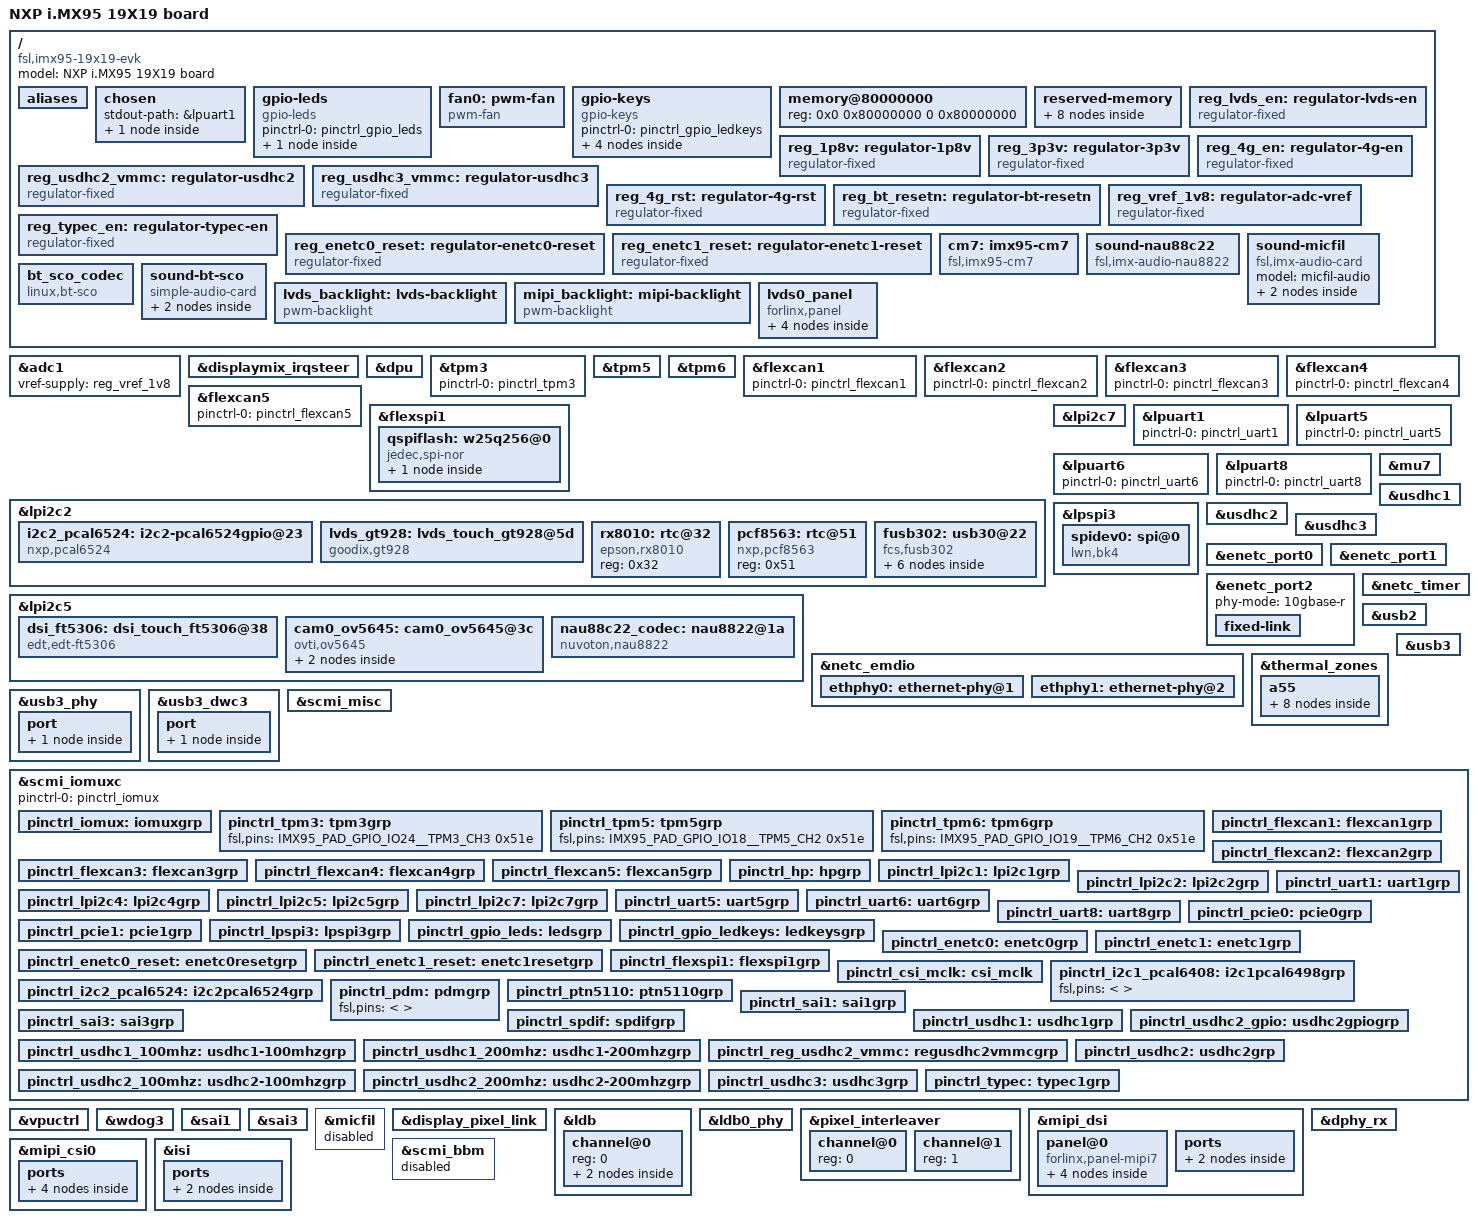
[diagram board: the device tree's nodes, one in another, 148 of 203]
// SPDX-License-Identifier: (GPL-2.0+ OR MIT)
/*
 * Copyright 2023 NXP
 */

/dts-v1/;

#include <dt-bindings/phy/phy-imx8-pcie.h>
#include <dt-bindings/pwm/pwm.h>
#include <dt-bindings/usb/pd.h>
#include "imx95.dtsi"

#define FALLING_EDGE		BIT(0)
#define RISING_EDGE		BIT(1)

#define BRD_SM_CTRL_SD3_WAKE		6	/*!< PCAL6408A-0 */
#define BRD_SM_CTRL_PCIE1_WAKE		7	/*!< PCAL6408A-4 */
#define BRD_SM_CTRL_BT_WAKE		8	/*!< PCAL6408A-5 */
#define BRD_SM_CTRL_PCIE2_WAKE		9	/*!< PCAL6408A-6 */
#define BRD_SM_CTRL_BUTTON		10	/*!< PCAL6408A-7 */

/ {
	model = "NXP i.MX95 19X19 board";
	compatible = "fsl,imx95-19x19-evk", "fsl,imx95";

	aliases {
		ethernet0 = &enetc_port0;
		ethernet1 = &enetc_port1;
		ethernet2 = &enetc_port2;
	};

	chosen {
		stdout-path = &lpuart1;
		#address-cells = <2>;
		#size-cells = <2>;
		/* will be updated by U-boot when booting Xen */
		module@0 {
			bootargs = "earlycon=xen console=hvc0 loglevel=8 root=/dev/mmcblk1p2 rw rootwait";
			compatible = "xen,linux-zimage", "xen,multiboot-module";
			reg = <0x00000000 0x9e000000 0x00000000 0x2000000>;
		};
	};

	gpio-leds {
		compatible = "gpio-leds";
		pinctrl-names = "default";
		pinctrl-0 = <&pinctrl_gpio_leds>;

		heartbeat {
			linux,default-trigger = "heartbeat";
			gpios = <&gpio3 27 GPIO_ACTIVE_HIGH>;
			default-state = "off";
		};
	};

	fan0: pwm-fan {
		compatible = "pwm-fan";
		cooling-min-state = <0>;
		cooling-max-state = <3>;
		#cooling-cells = <2>;
		pwms = <&tpm5 2 4000000 0>;
		cooling-levels = <0 80 160 255>;
	};

	gpio-keys {
		compatible = "gpio-keys";
		pinctrl-0 = <&pinctrl_gpio_ledkeys>;
		pinctrl-names = "default";

		button-a {
			gpios = <&gpio5 4 GPIO_ACTIVE_LOW>;
			label = "gpiokey-a";
			linux,code = <KEY_A>;
		};

		button-b {
			gpios = <&gpio5 5 GPIO_ACTIVE_LOW>;
			label = "gpiokey-b";
			linux,code = <KEY_B>;
		};

		button-c {
			gpios = <&gpio5 6 GPIO_ACTIVE_LOW>;
			label = "gpiokey-c";
			linux,code = <KEY_C>;
		};

		button-d {
			gpios = <&gpio5 7 GPIO_ACTIVE_LOW>;
			label = "gpiokey-d";
			linux,code = <KEY_D>;
		};
	};

	memory@80000000 {
		device_type = "memory";
		reg = <0x0 0x80000000 0 0x80000000>;
	};

	reserved-memory {
		#address-cells = <2>;
		#size-cells = <2>;
		ranges;

		linux_cma: linux,cma {
			compatible = "shared-dma-pool";
			reusable;
			size = <0 0x50000000>;
			alloc-ranges = <0 0x80000000 0 0x7F000000>;
			linux,cma-default;
		};

		vpu_boot: vpu_boot@a0000000 {
			reg = <0 0xa0000000 0 0x100000>;
			no-map;
		};

		vdev0vring0: vdev0vring0@88000000 {
			reg = <0 0x88000000 0 0x8000>;
			no-map;
		};

		vdev0vring1: vdev0vring1@88008000 {
			reg = <0 0x88008000 0 0x8000>;
			no-map;
		};

		vdev1vring0: vdev1vring0@88010000 {
			reg = <0 0x88010000 0 0x8000>;
			no-map;
		};

		vdev1vring1: vdev1vring1@88018000 {
			reg = <0 0x88018000 0 0x8000>;
			no-map;
		};

		rsc_table: rsc-table@88220000 {
			reg = <0 0x88220000 0 0x1000>;
			no-map;
		};

		vdevbuffer: vdevbuffer@88020000 {
			compatible = "shared-dma-pool";
			reg = <0 0x88020000 0 0x100000>;
			no-map;
		};
	};
/*
	reg_mipi_en: regulator-mipi-en {
		compatible = "regulator-fixed";
		regulator-name = "mipi-en";
		regulator-min-microvolt = <3300000>;
		regulator-max-microvolt = <3300000>;
		gpio = <&i2c2_pcal6524 17 GPIO_ACTIVE_HIGH>;
		enable-active-high;
		regulator-always-on;
	};
*/
	reg_lvds_en: regulator-lvds-en {
		compatible = "regulator-fixed";
		regulator-name = "lvds-en";
		regulator-min-microvolt = <3300000>;
		regulator-max-microvolt = <3300000>;
		gpio = <&i2c2_pcal6524 13 GPIO_ACTIVE_HIGH>;
		enable-active-high;
		regulator-always-on;
	};

	reg_1p8v: regulator-1p8v {
		compatible = "regulator-fixed";
		regulator-max-microvolt = <1800000>;
		regulator-min-microvolt = <1800000>;
		regulator-name = "+V1.8_SW";
	};

	reg_3p3v: regulator-3p3v {
		compatible = "regulator-fixed";
		regulator-max-microvolt = <3300000>;
		regulator-min-microvolt = <3300000>;
		regulator-name = "+V3.3_SW";
	};

        reg_usdhc2_vmmc: regulator-usdhc2 {
		compatible = "regulator-fixed";
		pinctrl-names = "default";
		pinctrl-0 = <&pinctrl_reg_usdhc2_vmmc>;
		regulator-name = "VDD_SD2_3V3";
		regulator-min-microvolt = <3300000>;
		regulator-max-microvolt = <3300000>;
		gpio = <&gpio3 7 GPIO_ACTIVE_HIGH>;
		off-on-delay-us = <12000>;
		enable-active-high;
	};

	reg_usdhc3_vmmc: regulator-usdhc3 {
		compatible = "regulator-fixed";
		regulator-name = "VDD_SD3_3V3";
		regulator-min-microvolt = <3300000>;
		regulator-max-microvolt = <3300000>;
		gpio = <&i2c2_pcal6524 4 GPIO_ACTIVE_HIGH>;
		enable-active-high;
	};

	reg_4g_en: regulator-4g-en {
		compatible = "regulator-fixed";
		regulator-name = "4g-en";
		regulator-min-microvolt = <3300000>;
		regulator-max-microvolt = <3300000>;
		gpio = <&i2c2_pcal6524 9 GPIO_ACTIVE_HIGH>;
		enable-active-high;
		regulator-always-on;
	};

	reg_4g_rst: regulator-4g-rst {
		compatible = "regulator-fixed";
		regulator-name = "4g-rst-3v3";
		regulator-min-microvolt = <3300000>;
		regulator-max-microvolt = <3300000>;
		gpio = <&i2c2_pcal6524 10 GPIO_ACTIVE_LOW>;
		enable-active-low;
		regulator-always-on;
	};

	reg_bt_resetn: regulator-bt-resetn {
		compatible = "regulator-fixed";
		regulator-name = "bt-resetn";
		regulator-min-microvolt = <3300000>;
		regulator-max-microvolt = <3300000>;
		gpio = <&i2c2_pcal6524 1 GPIO_ACTIVE_HIGH>;
		enable-active-high;
		regulator-always-on;
	};

/*
	reg_pcie0: regulator-pcie {
		compatible = "regulator-fixed";
		regulator-name = "PCIE_WLAN_EN";
		regulator-min-microvolt = <3300000>;
		regulator-max-microvolt = <3300000>;
		gpio = <&i2c7_pcal6524 6 GPIO_ACTIVE_HIGH>;
		enable-active-high;
		regulator-always-on;
	};
*/
	reg_vref_1v8: regulator-adc-vref {
		compatible = "regulator-fixed";
		regulator-name = "vref_1v8";
		regulator-min-microvolt = <1800000>;
		regulator-max-microvolt = <1800000>;
	};

	reg_typec_en: regulator-typec-en {
		compatible = "regulator-fixed";
		regulator-name = "typec-en";
		regulator-min-microvolt = <5000000>;
		regulator-max-microvolt = <5000000>;
		gpio = <&i2c2_pcal6524 20 GPIO_ACTIVE_HIGH>;
		enable-active-high;
	};

	reg_enetc0_reset: regulator-enetc0-reset {
		compatible = "regulator-fixed";
		pinctrl-names = "default";
		pinctrl-0 = <&pinctrl_enetc0_reset>;
		regulator-name = "VDD_ETH0_RST_3V3";
		regulator-min-microvolt = <3300000>;
		regulator-max-microvolt = <3300000>;
		gpio = <&gpio4 14 GPIO_ACTIVE_LOW>;
		enable-active-high;
		regulator-always-on;
	};
	reg_enetc1_reset: regulator-enetc1-reset {
		compatible = "regulator-fixed";
		pinctrl-names = "default";
		pinctrl-0 = <&pinctrl_enetc1_reset>;
		regulator-name = "VDD_ETH1_RST_3V3";
		regulator-min-microvolt = <3300000>;
		regulator-max-microvolt = <3300000>;
		gpio = <&gpio4 15 GPIO_ACTIVE_LOW>;
		enable-active-high;
		regulator-always-on;
	};

/*
	reg_usb_vbus: regulator-vbus {
		compatible = "regulator-fixed";
		regulator-name = "USB_VBUS";
		regulator-min-microvolt = <5000000>;
		regulator-max-microvolt = <5000000>;
		gpio = <&i2c7_pcal6524 3 GPIO_ACTIVE_HIGH>;
		enable-active-high;
		regulator-always-on;
	};

	reg_m2_pwr: regulator-m2-pwr {
		compatible = "regulator-fixed";
		regulator-name = "M.2-power";
		regulator-min-microvolt = <3300000>;
		regulator-max-microvolt = <3300000>;
		gpio = <&i2c7_pcal6524 20 GPIO_ACTIVE_HIGH>;
		enable-active-high;
		regulator-always-on;
	};

	reg_slot_pwr: regulator-slot-pwr {
		compatible = "regulator-fixed";
		regulator-name = "PCIe slot-power";
		regulator-min-microvolt = <3300000>;
		regulator-max-microvolt = <3300000>;
		gpio = <&i2c7_pcal6524 14 GPIO_ACTIVE_HIGH>;
		enable-active-high;
		regulator-always-on;
	};

	reg_aqr_stby: regulator-aqr-stby {
		compatible = "regulator-fixed";
		regulator-name = "aqr-stby";
		regulator-min-microvolt = <3300000>;
		regulator-max-microvolt = <3300000>;
		gpio = <&i2c5_gpio_expander_21 1 GPIO_ACTIVE_HIGH>;
		enable-active-high;
		regulator-always-on;
	};

	reg_aqr_en: regulator-aqr-en {
		compatible = "regulator-fixed";
		regulator-name = "aqr-en";
		regulator-min-microvolt = <3300000>;
		regulator-max-microvolt = <3300000>;
		vin-supply = <&reg_aqr_stby>;
		gpio = <&i2c5_gpio_expander_21 0 GPIO_ACTIVE_HIGH>;
		enable-active-high;
	};

	reg_serdes_stby: regulator-mac-stby {
		compatible = "regulator-fixed";
		regulator-name = "mac-stby";
		regulator-min-microvolt = <3300000>;
		regulator-max-microvolt = <3300000>;
		gpio = <&i2c7_pcal6524 13 GPIO_ACTIVE_LOW>;
		regulator-always-on;
	};

	reg_serdes_en: regulator-mac-en {
		compatible = "regulator-fixed";
		regulator-name = "mac-en";
		regulator-min-microvolt = <3300000>;
		regulator-max-microvolt = <3300000>;
		vin-supply = <&reg_serdes_stby>;
		gpio = <&i2c5_gpio_expander_21 3 GPIO_ACTIVE_LOW>;
	};
*/
	cm7: imx95-cm7 {
		compatible = "fsl,imx95-cm7";
		mbox-names = "tx", "rx", "rxdb";
		mboxes = <&mu7 0 1
			  &mu7 1 1
			  &mu7 3 1>;
		memory-region = <&vdevbuffer>, <&vdev0vring0>, <&vdev0vring1>,
				<&vdev1vring0>, <&vdev1vring1>, <&rsc_table>;
		fsl,startup-delay-ms = <50>;
		status = "okay";
	};

	sound-nau88c22 {
		compatible = "fsl,imx-audio-nau8822";
		pinctrl-names = "default";
		pinctrl-0 = <&pinctrl_hp>;
		model = "nau88c22-audio";
		audio-cpu = <&sai3>;
		audio-codec = <&nau88c22_codec>;
		hp-det-gpio = <&gpio5 14 GPIO_ACTIVE_HIGH>;
		audio-routing =
			"Headphone Jack", "LHP",
			"Headphone Jack", "RHP",
			"Ext Spk", "LSPK",
			"Ext Spk", "RSPK",
			"LMICN", "Mic Jack",
			"LMICP", "Mic Jack",
			"RMICN", "Mic Jack",
			"RMICP", "Mic Jack";
	};

	sound-micfil {
		compatible = "fsl,imx-audio-card";
		model = "micfil-audio";
		pri-dai-link {
			link-name = "micfil hifi";
			format = "i2s";
			cpu {
				sound-dai = <&micfil>;
			};
		};
	};

	bt_sco_codec: bt_sco_codec {
		#sound-dai-cells = <1>;
		compatible = "linux,bt-sco";
	};

	sound-bt-sco {
		compatible = "simple-audio-card";
		simple-audio-card,name = "bt-sco-audio";
		simple-audio-card,format = "dsp_a";
		simple-audio-card,bitclock-inversion;
		simple-audio-card,frame-master = <&btcpu>;
		simple-audio-card,bitclock-master = <&btcpu>;

		btcpu: simple-audio-card,cpu {
			sound-dai = <&sai1>;
			dai-tdm-slot-num = <2>;
			dai-tdm-slot-width = <16>;
		};

		simple-audio-card,codec {
			sound-dai = <&bt_sco_codec 1>;
		};
	};

	lvds_backlight: lvds-backlight {
		compatible = "pwm-backlight";
		pwms = <&tpm3 3 50000 0>;
		is-forlinx;      //if not forlinx backligth  remove this
		status = "okay";
		brightness-levels = <
			0   1   2   3   4   5   6   7
			8   9  10  11  12  13  14  15
			16  17  18  19  20  21  22  23
			24  25  26  27  28  29  30  31
			32  33  34  35  36  37  38  39
			40  41  42  43  44  45  46  47
			48  49  50  51  52  53  54  55
			56  57  58  59  60  61  62  63
			64  65  66  67  68  69  70  71
			72  73  74  75  76  77  78  79
			80  81  82  83  84  85  86  87
			88  89  90  91  92  93  94  95
			96  97  98  99 100 101 102 103
			104 105 106 107 108 109 110 111
			112 113 114 115 116 117 118 119
			120 121 122 123 124 125 126 127
			128 129 130 131 132 133 134 135
			136 137 138 139 140 141 142 143
			144 145 146 147 148 149 150 151
			152 153 154 155 156 157 158 159
			160 161 162 163 164 165 166 167
			168 169 170 171 172 173 174 175
			176 177 178 179 180 181 182 183
			184 185 186 187 188 189 190 191
			192 193 194 195 196 197 198 199
			200 201 202 203 204 205 206 207
			208 209 210 211 212 213 214 215
			216 217 218 219 220 221 222 223
			224 225 226 227 228 229 230 231
			232 233 234 235 236 237 238 239
			240 241 242 243 244 245 246 247
			248 249 250 251 252 253 254 255
		>;
		default-brightness-level = <250>;
	};

	mipi_backlight: mipi-backlight {
		compatible = "pwm-backlight";
		pwms = <&tpm6 2 50000 0>;
		is-forlinx;      //if not forlinx backligth  remove this
		status = "okay";
		brightness-levels = <
			0   1   2   3   4   5   6   7
			8   9  10  11  12  13  14  15
			16  17  18  19  20  21  22  23
			24  25  26  27  28  29  30  31
			32  33  34  35  36  37  38  39
			40  41  42  43  44  45  46  47
			48  49  50  51  52  53  54  55
			56  57  58  59  60  61  62  63
			64  65  66  67  68  69  70  71
			72  73  74  75  76  77  78  79
			80  81  82  83  84  85  86  87
			88  89  90  91  92  93  94  95
			96  97  98  99 100 101 102 103
			104 105 106 107 108 109 110 111
			112 113 114 115 116 117 118 119
			120 121 122 123 124 125 126 127
			128 129 130 131 132 133 134 135
			136 137 138 139 140 141 142 143
			144 145 146 147 148 149 150 151
			152 153 154 155 156 157 158 159
			160 161 162 163 164 165 166 167
			168 169 170 171 172 173 174 175
			176 177 178 179 180 181 182 183
			184 185 186 187 188 189 190 191
			192 193 194 195 196 197 198 199
			200 201 202 203 204 205 206 207
			208 209 210 211 212 213 214 215
			216 217 218 219 220 221 222 223
			224 225 226 227 228 229 230 231
			232 233 234 235 236 237 238 239
			240 241 242 243 244 245 246 247
			248 249 250 251 252 253 254 255
		>;
		default-brightness-level = <250>;
	};
};

&adc1 {
	vref-supply = <&reg_vref_1v8>;
	status = "okay";
};

&displaymix_irqsteer {
	status = "okay";
};

&dpu {
	status = "okay";
	assigned-clocks = <&scmi_clk IMX95_CLK_DISP1PIX>,
			  <&scmi_clk IMX95_CLK_VIDEOPLL1_VCO>,
			  <&scmi_clk IMX95_CLK_VIDEOPLL1>;
	assigned-clock-parents = <&scmi_clk IMX95_CLK_VIDEOPLL1>;
	assigned-clock-rates = <0>, <4008000000>, <445333334>;
};

&tpm3 {
	pinctrl-names = "default";
	pinctrl-0 = <&pinctrl_tpm3>;
	status = "okay";
};

&tpm5 {
	pinctrl-names = "default";
	pinctrl-0 = <&pinctrl_tpm5>;
	pwm-rst;
	status = "okay";
};

&tpm6 {
	pinctrl-names = "default";
	pinctrl-0 = <&pinctrl_tpm6>;
	pwm-rst;
	status = "okay";
};

&flexcan1 {
	pinctrl-names = "default";
	pinctrl-0 = <&pinctrl_flexcan1>;
	status = "okay";
};

&flexcan2 {
	pinctrl-names = "default";
	pinctrl-0 = <&pinctrl_flexcan2>;
	status = "okay";
};

&flexcan3 {
        pinctrl-names = "default";
        pinctrl-0 = <&pinctrl_flexcan3>;
        status = "okay";
};

&flexcan4 {
        pinctrl-names = "default";
        pinctrl-0 = <&pinctrl_flexcan4>;
        status = "okay";
};

&flexcan5 {
        pinctrl-names = "default";
        pinctrl-0 = <&pinctrl_flexcan5>;
        status = "okay";
};

&flexspi1 {
	pinctrl-names = "default", "sleep";
	pinctrl-0 = <&pinctrl_flexspi1>;
	pinctrl-1 = <&pinctrl_flexspi1>;
	status = "okay";

	pinctrl-assert-gpios = <&gpio5 11 GPIO_ACTIVE_HIGH>;

        qspiflash: w25q256@0 {
                reg = <0>;
                #address-cells = <1>;
                #size-cells = <1>;
                compatible = "jedec,spi-nor";
                spi-max-frequency = <80000000>;
                spi-tx-bus-width = <1>;
                spi-rx-bus-width = <4>;

                partition@0 {
                        label = "qspiflash";
                        reg = <0x0 0x2000000>;
                };
        };

};

&lpi2c2 {
	#address-cells = <1>;
	#size-cells = <0>;
	clock-frequency = <400000>;
	pinctrl-names = "default", "sleep";
	pinctrl-0 = <&pinctrl_lpi2c2>;
	pinctrl-1 = <&pinctrl_lpi2c2>;
	status = "okay";

	/* I/O expand in carrier */
	i2c2_pcal6524: i2c2-pcal6524gpio@23 {
		compatible = "nxp,pcal6524";
		pinctrl-names = "default";
		pinctrl-0 = <&pinctrl_i2c2_pcal6524>;
		reg = <0x23>;
		gpio-controller;
		#gpio-cells = <2>;
		interrupt-controller;
		#interrupt-cells = <2>;
		interrupt-parent = <&gpio5>;
		interrupts = <16 IRQ_TYPE_EDGE_FALLING>;
	};

	lvds_gt928: lvds_touch_gt928@5d {
		compatible = "goodix,gt928";
		reg = <0x5d>;
		irq-gpios = <&i2c2_pcal6524 14 GPIO_ACTIVE_HIGH>; //P16
		reset-gpios = <&i2c2_pcal6524 12 GPIO_ACTIVE_HIGH>; //P14
		interrupt-parent = <&i2c2_pcal6524>;
		interrupts = <14 IRQ_TYPE_EDGE_FALLING>; //P16
		touchscreen-size-x = <1280>;
		touchscreen-size-y = <800>;
		touchscreen-swapped-x-y;
		status = "okay";
	};

	rx8010:rtc@32 {
		compatible = "epson,rx8010";
		reg = <0x32>;
		status = "okay";
	};

	pcf8563:rtc@51 {
		compatible = "nxp,pcf8563";
		reg = <0x51>;
		status = "okay";
	};

	fusb302: usb30@22 {
		compatible = "fcs,fusb302";
		reg = <0x22>;
		pinctrl-names = "default";
		pinctrl-0 = <&pinctrl_typec>;
		interrupt-parent = <&gpio5>;
		interrupts = <15 IRQ_TYPE_EDGE_FALLING>;
		vbus-supply = <&reg_typec_en>;
		status = "okay";

		port {
			typec_dr_sw: endpoint {
				remote-endpoint = <&usb3_drd_sw>;
			};
		};

		typec_con: connector {
			compatible = "usb-c-connector";
			label = "USB-C";
			power-role = "dual";
			data-role = "dual";
			try-power-role = "source";
			op-sink-microwatt = <10000000>;
			source-pdos = <PDO_FIXED(5000, 1500, PDO_FIXED_USB_COMM)>;
			sink-pdos = <PDO_FIXED(5000, 1500, PDO_FIXED_USB_COMM)>;
			self-powered;

			ports {
				#address-cells = <1>;
				#size-cells = <0>;

				port@1 {
					reg = <1>;
					typec_con_ss: endpoint {
						remote-endpoint = <&usb3_data_ss>;
					};
				};
			};
		};
	};
};

&lpi2c5 {
	#address-cells = <1>;
	#size-cells = <0>;
	clock-frequency = <100000>;
	pinctrl-names = "default", "sleep";
	pinctrl-0 = <&pinctrl_lpi2c5>;
	pinctrl-1 = <&pinctrl_lpi2c5>;
	status = "okay";

	dsi_ft5306: dsi_touch_ft5306@38 {
		compatible = "edt,edt-ft5306";
		reg = <0x38>;
		interrupt-parent = <&i2c2_pcal6524>;
		interrupts = <15 IRQ_TYPE_EDGE_FALLING>; //P17
		touchscreen-size-x = <1024>;
		touchscreen-size-y = <600>;
		status = "okay";
	};

	cam0_ov5645: cam0_ov5645@3c {
		compatible = "ovti,ov5645";
		status = "okay";
		reg = <0x3c>;

		pinctrl-names = "default";
		pinctrl-0 = <&pinctrl_csi_mclk>;
		clocks = <&scmi_clk IMX95_CLK_CCMCKO1>;
		clock-names = "xvclk";
		clock-frequency = <24000000>;
		assigned-clocks = <&scmi_clk IMX95_CLK_CCMCKO1>;
		assigned-clock-parents = <&osc_24m>;
		assigned-clock-rates = <24000000>;
		mclk = <24000000>;

		enable-gpios = <&i2c2_pcal6524 8 GPIO_ACTIVE_HIGH>; //P10
		reset-gpios = <&i2c2_pcal6524 7 GPIO_ACTIVE_LOW>; //P07

		port {
			mipi_cam0_ep: endpoint {
				remote-endpoint = <&mipi_csi0_ep>;
				data-lanes = <1 2>;
				clock-lanes = <0>;
				link-frequencies = /bits/ 64 <336000000>;
			};
		};
	};

	nau88c22_codec: nau8822@1a {
		compatible = "nuvoton,nau8822";
		reg = <0x1a>;
		clocks = <&scmi_clk IMX95_CLK_SAI3>;
		clock-names = "mclk";
		#sound-dai-cells = <0>;
		status = "okay";
	};

};

&lpi2c7 {
	#address-cells = <1>;
	#size-cells = <0>;
	clock-frequency = <1000000>;
	pinctrl-names = "default", "sleep";
	pinctrl-0 = <&pinctrl_lpi2c7>;
	pinctrl-1 = <&pinctrl_lpi2c7>;
	status = "okay";

};

&lpuart1 {
	/* console */
	pinctrl-names = "default";
	pinctrl-0 = <&pinctrl_uart1>;
	status = "okay";
};

&lpuart5 {
	/* BT */
	pinctrl-names = "default";
	pinctrl-0 = <&pinctrl_uart5>;
	status = "okay";
};

&lpuart6 {
	/* RS485 */
	pinctrl-names = "default";
	pinctrl-0 = <&pinctrl_uart6>;
	status = "okay";
	/delete-property/ dmas;
	/delete-property/ dma-names;
};

&lpuart8 {
	/* RS485 */
	pinctrl-names = "default";
	pinctrl-0 = <&pinctrl_uart8>;
	status = "okay";
	/delete-property/ dmas;
	/delete-property/ dma-names;
};

&lpspi3 {
        fsl,spi-num-chipselects = <1>;
        pinctrl-names = "default", "sleep";
        pinctrl-0 = <&pinctrl_lpspi3>;
        pinctrl-1 = <&pinctrl_lpspi3>;
        cs-gpios = <&gpio2 8 GPIO_ACTIVE_LOW>;
        status = "okay";

        spidev0: spi@0 {
                reg = <0>;
                compatible = "lwn,bk4";
                spi-max-frequency = <1000000>;
        };
};

&mu7 {
	status = "okay";
};

&usdhc1 {
	pinctrl-names = "default", "state_100mhz", "state_200mhz", "sleep";
	pinctrl-0 = <&pinctrl_usdhc1>;
	pinctrl-1 = <&pinctrl_usdhc1_100mhz>;
	pinctrl-2 = <&pinctrl_usdhc1_200mhz>;
	pinctrl-3 = <&pinctrl_usdhc1>;
	bus-width = <8>;
	non-removable;
	no-sdio;
	no-sd;
	status = "okay";
};

&usdhc2 {
	pinctrl-names = "default", "state_100mhz", "state_200mhz", "sleep";
	pinctrl-0 = <&pinctrl_usdhc2>, <&pinctrl_usdhc2_gpio>;
	pinctrl-1 = <&pinctrl_usdhc2_100mhz>, <&pinctrl_usdhc2_gpio>;
	pinctrl-2 = <&pinctrl_usdhc2_200mhz>, <&pinctrl_usdhc2_gpio>;
	pinctrl-3 = <&pinctrl_usdhc2>, <&pinctrl_usdhc2_gpio>;
	cd-gpios = <&gpio3 00 GPIO_ACTIVE_LOW>;
	vmmc-supply = <&reg_usdhc2_vmmc>;
	bus-width = <4>;
	status = "okay";
};

&usdhc3 {
	pinctrl-names = "default";
	pinctrl-0 = <&pinctrl_usdhc3>;
	bus-width = <4>;
	non-removable;
	keep-power-in-suspend;
	vmmc-supply = <&reg_usdhc3_vmmc>;
	status = "okay";
};

&enetc_port0 {
	pinctrl-names = "default";
	pinctrl-0 = <&pinctrl_enetc0>;
	phy-handle = <&ethphy0>;
	phy-mode = "rgmii-id";
	status = "okay";
};

&enetc_port1 {
	pinctrl-names = "default";
	pinctrl-0 = <&pinctrl_enetc1>;
	phy-handle = <&ethphy1>;
	phy-mode = "rgmii-id";
	status = "okay";
};

&enetc_port2 {

	phy-mode = "10gbase-r";
	status = "okay";
	fixed-link {
		speed = <10000>;
		full-duplex;
	};
};

&netc_timer {
	status = "okay";
};

&netc_emdio {
	//phy-supply = <&reg_aqr_en>;
	status = "okay";

	ethphy0: ethernet-phy@1 {
		reg = <1>;
//		pinctrl-names = "default";
//		pinctrl-0 = <&pinctrl_enetc0_reset>;
		eee-broken-1000t;
//		reset-gpios = <&gpio4 14 GPIO_ACTIVE_LOW>;
		reset-assert-us = <10000>;
		reset-deassert-us = <80000>;
	};

	ethphy1: ethernet-phy@2 {
		reg = <2>;
//		pinctrl-names = "default";
//		pinctrl-0 = <&pinctrl_enetc1_reset>;
		eee-broken-1000t;
//		reset-gpios = <&gpio4 15 GPIO_ACTIVE_LOW>;
		reset-assert-us = <10000>;
		reset-deassert-us = <80000>;
	};
};

&usb2 {
	dr_mode = "host";
	//vbus-supply = <&reg_usb_vbus>;
	disable-over-current;
	status = "okay";
};

&thermal_zones {
	a55 {
		trips {
			atrip2: trip2 {
				temperature = <55000>;
				hysteresis = <2000>;
				type = "active";
			};

			atrip3: trip3 {
				temperature = <65000>;
				hysteresis = <2000>;
				type = "active";
			};

			atrip4: trip4 {
				temperature = <75000>;
				hysteresis = <2000>;
				type = "active";
			};
		};

		cooling-maps {
			map1 {
				trip = <&atrip2>;
				cooling-device = <&fan0 0 1>;
			};

			map2 {
				trip = <&atrip3>;
				cooling-device = <&fan0 1 2>;
			};

			map3 {
				trip = <&atrip4>;
				cooling-device = <&fan0 2 3>;
			};
		};
	};
};

&usb3 {
	status = "okay";
};

&usb3_phy {
	status = "okay";
	port {
		usb3_data_ss: endpoint {
			remote-endpoint = <&typec_con_ss>;
		};
	};
};

&usb3_dwc3 {
	dr_mode = "otg";
	hnp-disable;
	srp-disable;
	adp-disable;
	usb-role-switch;
	role-switch-default-mode = "none";
	snps,dis-u1-entry-quirk;
	snps,dis-u2-entry-quirk;
	status = "okay";

	port {
		usb3_drd_sw: endpoint {
			remote-endpoint = <&typec_dr_sw>;
		};
	};
};

&scmi_misc {
	wakeup-sources = <BRD_SM_CTRL_SD3_WAKE		1
			  BRD_SM_CTRL_PCIE1_WAKE	1
			  BRD_SM_CTRL_BT_WAKE		1
			  BRD_SM_CTRL_PCIE2_WAKE	1
			  BRD_SM_CTRL_BUTTON		1>;
};

&scmi_iomuxc {
	pinctrl-names = "default";
	pinctrl-0 = <&pinctrl_iomux>;
	pinctrl_iomux: iomuxgrp {
		fsl,pins = <
			IMX95_PAD_GPIO_IO37__GPIO5_IO_BIT17			0x11e //buzzer
		>;
	};

	pinctrl_tpm3: tpm3grp {
		fsl,pins = <
			IMX95_PAD_GPIO_IO24__TPM3_CH3			0x51e
		>;
	};

	pinctrl_tpm5: tpm5grp {
		fsl,pins = <
			IMX95_PAD_GPIO_IO18__TPM5_CH2			0x51e
		>;
	};

	pinctrl_tpm6: tpm6grp {
		fsl,pins = <
			IMX95_PAD_GPIO_IO19__TPM6_CH2			0x51e
		>;
	};

	pinctrl_flexcan1: flexcan1grp {
		fsl,pins = <
			IMX95_PAD_PDM_CLK__AONMIX_TOP_CAN1_TX		0x39e
			IMX95_PAD_PDM_BIT_STREAM0__AONMIX_TOP_CAN1_RX	0x39e
		>;
	};

	pinctrl_flexcan2: flexcan2grp {
		fsl,pins = <
			IMX95_PAD_GPIO_IO25__CAN2_TX			0x39e
			IMX95_PAD_GPIO_IO27__CAN2_RX			0x39e
		>;
	};

	pinctrl_flexcan3: flexcan3grp {
		fsl,pins = <
			IMX95_PAD_GPIO_IO28__CAN3_TX			0x39e
			IMX95_PAD_GPIO_IO29__CAN3_RX			0x39e
		>;
	};

	pinctrl_flexcan4: flexcan4grp {
		fsl,pins = <
			IMX95_PAD_GPIO_IO04__CAN4_TX			0x39e
			IMX95_PAD_GPIO_IO05__CAN4_RX			0x39e
		>;
	};

	pinctrl_flexcan5: flexcan5grp {
		fsl,pins = <
			IMX95_PAD_GPIO_IO30__CAN5_TX			0x39e
			IMX95_PAD_GPIO_IO31__CAN5_RX			0x39e
		>;
	};

	pinctrl_hp: hpgrp {
		fsl,pins = <
			IMX95_PAD_GPIO_IO34__GPIO5_IO_BIT14		0x31e
		>;
	};

	pinctrl_lpi2c1: lpi2c1grp {
		fsl,pins = <
			IMX95_PAD_I2C1_SCL__AONMIX_TOP_LPI2C1_SCL	0x40000b9e
			IMX95_PAD_I2C1_SDA__AONMIX_TOP_LPI2C1_SDA	0x40000b9e
		>;
	};

	pinctrl_lpi2c2: lpi2c2grp {
		fsl,pins = <
			IMX95_PAD_I2C2_SCL__AONMIX_TOP_LPI2C2_SCL	0x40000b9e
			IMX95_PAD_I2C2_SDA__AONMIX_TOP_LPI2C2_SDA	0x40000b9e
		>;
	};

	pinctrl_lpi2c4: lpi2c4grp {
		fsl,pins = <
			IMX95_PAD_GPIO_IO30__LPI2C4_SDA			0x40000b9e
			IMX95_PAD_GPIO_IO31__LPI2C4_SCL			0x40000b9e
		>;
	};

	pinctrl_lpi2c5: lpi2c5grp {
		fsl,pins = <
			IMX95_PAD_GPIO_IO22__LPI2C5_SDA			0x40000b9e
			IMX95_PAD_GPIO_IO23__LPI2C5_SCL			0x40000b9e
		>;
	};

	pinctrl_lpi2c7: lpi2c7grp {
		fsl,pins = <
			IMX95_PAD_GPIO_IO06__LPI2C7_SDA			0x40000b9e
			IMX95_PAD_GPIO_IO07__LPI2C7_SCL			0x40000b9e
		>;
	};

	pinctrl_uart1: uart1grp {
		fsl,pins = <
			IMX95_PAD_UART1_RXD__AONMIX_TOP_LPUART1_RX	0x31e
			IMX95_PAD_UART1_TXD__AONMIX_TOP_LPUART1_TX	0x31e
		>;
	};

	pinctrl_uart5: uart5grp {
		fsl,pins = <
			IMX95_PAD_GPIO_IO00__LPUART5_TX			0x31e
			IMX95_PAD_GPIO_IO01__LPUART5_RX			0x31e
			IMX95_PAD_GPIO_IO02__LPUART5_CTS_B		0x31e
			IMX95_PAD_GPIO_IO03__LPUART5_RTS_B		0x31e
		>;
	};

	pinctrl_uart6: uart6grp {
		fsl,pins = <
			IMX95_PAD_GPIO_IO33__LPUART6_RX					0x31e
			IMX95_PAD_GPIO_IO32__LPUART6_TX					0x31e
		>;
	};

	pinctrl_uart8: uart8grp {
		fsl,pins = <
			IMX95_PAD_GPIO_IO13__LPUART8_RX					0x31e
			IMX95_PAD_GPIO_IO12__LPUART8_TX					0x31e
		>;
	};

	pinctrl_pcie0: pcie0grp {
		fsl,pins = <
			IMX95_PAD_GPIO_IO32__HSIOMIX_TOP_PCIE1_CLKREQ_B		0x40000b1e
		>;
	};

	pinctrl_pcie1: pcie1grp {
		fsl,pins = <
			IMX95_PAD_GPIO_IO35__HSIOMIX_TOP_PCIE2_CLKREQ_B		0x40000b1e
		>;
	};

	pinctrl_lpspi3: lpspi3grp {
		fsl,pins = <
			IMX95_PAD_GPIO_IO08__LPSPI3_PCS0					0x3fe
			IMX95_PAD_GPIO_IO09__LPSPI3_SIN						0x3fe
			IMX95_PAD_GPIO_IO10__LPSPI3_SOUT					0x3fe
			IMX95_PAD_GPIO_IO11__LPSPI3_SCK						0x3fe
		>;
	};

	pinctrl_gpio_leds: ledsgrp {
		fsl,pins = <
			IMX95_PAD_CCM_CLKO2__GPIO3_IO_BIT27					0x31e /* gpio leds, Output pull-up */
		>;
	};

	pinctrl_gpio_ledkeys: ledkeysgrp {
		fsl,pins = <
			IMX95_PAD_XSPI1_DATA4__GPIO5_IO_BIT4				0x176 /* gpio key, Input pull-up. */
			IMX95_PAD_XSPI1_DATA5__GPIO5_IO_BIT5				0x176 /* gpio key, Input pull-up. */
			IMX95_PAD_XSPI1_DATA6__GPIO5_IO_BIT6				0x176 /* gpio key, Input pull-up. */
			IMX95_PAD_XSPI1_DATA7__GPIO5_IO_BIT7				0x176 /* gpio key, Input pull-up. */
		>;
	};

	pinctrl_enetc0: enetc0grp {
		fsl,pins = <
			IMX95_PAD_ENET1_MDC__NETCMIX_TOP_NETC_MDC		0x57e
			IMX95_PAD_ENET1_MDIO__NETCMIX_TOP_NETC_MDIO		0x57e
			IMX95_PAD_ENET1_TD3__NETCMIX_TOP_ETH0_RGMII_TD3		0x57e
			IMX95_PAD_ENET1_TD2__NETCMIX_TOP_ETH0_RGMII_TD2		0x57e
			IMX95_PAD_ENET1_TD1__NETCMIX_TOP_ETH0_RGMII_TD1		0x57e
			IMX95_PAD_ENET1_TD0__NETCMIX_TOP_ETH0_RGMII_TD0		0x57e
			IMX95_PAD_ENET1_TX_CTL__NETCMIX_TOP_ETH0_RGMII_TX_CTL	0x57e
			IMX95_PAD_ENET1_TXC__NETCMIX_TOP_ETH0_RGMII_TX_CLK	0x5fe
			IMX95_PAD_ENET1_RX_CTL__NETCMIX_TOP_ETH0_RGMII_RX_CTL	0x57e
			IMX95_PAD_ENET1_RXC__NETCMIX_TOP_ETH0_RGMII_RX_CLK	0x5fe
			IMX95_PAD_ENET1_RD0__NETCMIX_TOP_ETH0_RGMII_RD0		0x57e
			IMX95_PAD_ENET1_RD1__NETCMIX_TOP_ETH0_RGMII_RD1		0x57e
			IMX95_PAD_ENET1_RD2__NETCMIX_TOP_ETH0_RGMII_RD2		0x57e
			IMX95_PAD_ENET1_RD3__NETCMIX_TOP_ETH0_RGMII_RD3		0x57e
		>;
	};

	pinctrl_enetc1: enetc1grp {
		fsl,pins = <
			IMX95_PAD_ENET2_TD3__NETCMIX_TOP_ETH1_RGMII_TD3		0x57e
			IMX95_PAD_ENET2_TD2__NETCMIX_TOP_ETH1_RGMII_TD2		0x57e
			IMX95_PAD_ENET2_TD1__NETCMIX_TOP_ETH1_RGMII_TD1		0x57e
			IMX95_PAD_ENET2_TD0__NETCMIX_TOP_ETH1_RGMII_TD0		0x57e
			IMX95_PAD_ENET2_TX_CTL__NETCMIX_TOP_ETH1_RGMII_TX_CTL	0x57e
			IMX95_PAD_ENET2_TXC__NETCMIX_TOP_ETH1_RGMII_TX_CLK	0x5fe
			IMX95_PAD_ENET2_RX_CTL__NETCMIX_TOP_ETH1_RGMII_RX_CTL	0x57e
			IMX95_PAD_ENET2_RXC__NETCMIX_TOP_ETH1_RGMII_RX_CLK	0x5fe
			IMX95_PAD_ENET2_RD0__NETCMIX_TOP_ETH1_RGMII_RD0		0x57e
			IMX95_PAD_ENET2_RD1__NETCMIX_TOP_ETH1_RGMII_RD1		0x57e
			IMX95_PAD_ENET2_RD2__NETCMIX_TOP_ETH1_RGMII_RD2		0x57e
			IMX95_PAD_ENET2_RD3__NETCMIX_TOP_ETH1_RGMII_RD3		0x57e
		>;
	};

	pinctrl_enetc0_reset: enetc0resetgrp {
		fsl,pins = <
			IMX95_PAD_ENET2_MDC__GPIO4_IO_BIT14					0x31e // reset
		>;
	};

	pinctrl_enetc1_reset: enetc1resetgrp {
		fsl,pins = <
			IMX95_PAD_ENET2_MDIO__GPIO4_IO_BIT15				0x31e // reset
		>;
	};

	pinctrl_flexspi1: flexspi1grp {
		fsl,pins = <
			IMX95_PAD_XSPI1_SS0_B__FLEXSPI1_A_SS0_B			0x3fe
			IMX95_PAD_XSPI1_SS1_B__GPIO5_IO_BIT11			0x3fe
			IMX95_PAD_XSPI1_SCLK__FLEXSPI1_A_SCLK			0x3fe
			IMX95_PAD_XSPI1_DQS__FLEXSPI1_A_DQS			0x3fe
			IMX95_PAD_XSPI1_DATA0__FLEXSPI1_A_DATA_BIT0		0x3fe
			IMX95_PAD_XSPI1_DATA1__FLEXSPI1_A_DATA_BIT1		0x3fe
			IMX95_PAD_XSPI1_DATA2__FLEXSPI1_A_DATA_BIT2		0x3fe
			IMX95_PAD_XSPI1_DATA3__FLEXSPI1_A_DATA_BIT3		0x3fe
		>;
	};

	pinctrl_csi_mclk: csi_mclk {
		fsl,pins = <
			IMX95_PAD_CCM_CLKO1__CCMSRCGPCMIX_TOP_CLKO_1	0x39e
		>;
	};

	pinctrl_i2c1_pcal6408: i2c1pcal6498grp {
		fsl,pins = <
			//TODO
			//IMX95_PAD_PDM_BIT_STREAM1__AONMIX_TOP_GPIO1_IO_BIT10	0x31e
		>;
	};

	pinctrl_i2c2_pcal6524: i2c2pcal6524grp {
		fsl,pins = <
			IMX95_PAD_GPIO_IO36__GPIO5_IO_BIT16			0x31e
		>;
	};

	pinctrl_pdm: pdmgrp {
		fsl,pins = <
			//IMX95_PAD_PDM_CLK__AONMIX_TOP_PDM_CLK				0x31e
			//IMX95_PAD_PDM_BIT_STREAM0__AONMIX_TOP_PDM_BIT_STREAM_BIT0	0x31e
		>;
	};

	pinctrl_ptn5110: ptn5110grp {
		fsl,pins = <
			IMX95_PAD_GPIO_IO34__GPIO5_IO_BIT14			0x31e
		>;
	};

	pinctrl_sai1: sai1grp {
		fsl,pins = <
			IMX95_PAD_SAI1_TXC__AONMIX_TOP_SAI1_TX_BCLK		0x31e
			IMX95_PAD_SAI1_TXFS__AONMIX_TOP_SAI1_TX_SYNC		0x31e
			IMX95_PAD_SAI1_TXD0__AONMIX_TOP_SAI1_TX_DATA_BIT0	0x31e
			IMX95_PAD_SAI1_RXD0__AONMIX_TOP_SAI1_RX_DATA_BIT0	0x31e
		>;
	};

	pinctrl_sai3: sai3grp {
		fsl,pins = <
			IMX95_PAD_GPIO_IO17__SAI3_MCLK				0x31e
			IMX95_PAD_GPIO_IO16__SAI3_TX_BCLK			0x31e
			IMX95_PAD_GPIO_IO26__SAI3_TX_SYNC			0x31e
			IMX95_PAD_GPIO_IO20__SAI3_RX_DATA_BIT0			0x31e
			IMX95_PAD_GPIO_IO21__SAI3_TX_DATA_BIT0			0x31e
		>;
	};

	pinctrl_spdif: spdifgrp {
		fsl,pins = <
			IMX95_PAD_GPIO_IO22__SPDIF_IN				0x31e
			IMX95_PAD_GPIO_IO23__SPDIF_OUT				0x31e
		>;
	};

	pinctrl_usdhc1: usdhc1grp {
		fsl,pins = <
			IMX95_PAD_SD1_CLK__USDHC1_CLK				0x158e
			IMX95_PAD_SD1_CMD__USDHC1_CMD				0x138e
			IMX95_PAD_SD1_DATA0__USDHC1_DATA0			0x138e
			IMX95_PAD_SD1_DATA1__USDHC1_DATA1			0x138e
			IMX95_PAD_SD1_DATA2__USDHC1_DATA2			0x138e
			IMX95_PAD_SD1_DATA3__USDHC1_DATA3			0x138e
			IMX95_PAD_SD1_DATA4__USDHC1_DATA4			0x138e
			IMX95_PAD_SD1_DATA5__USDHC1_DATA5			0x138e
			IMX95_PAD_SD1_DATA6__USDHC1_DATA6			0x138e
			IMX95_PAD_SD1_DATA7__USDHC1_DATA7			0x138e
			IMX95_PAD_SD1_STROBE__USDHC1_STROBE			0x158e
		>;
	};

	pinctrl_usdhc1_100mhz: usdhc1-100mhzgrp {
		fsl,pins = <
			IMX95_PAD_SD1_CLK__USDHC1_CLK				0x158e
			IMX95_PAD_SD1_CMD__USDHC1_CMD				0x138e
			IMX95_PAD_SD1_DATA0__USDHC1_DATA0			0x138e
			IMX95_PAD_SD1_DATA1__USDHC1_DATA1			0x138e
			IMX95_PAD_SD1_DATA2__USDHC1_DATA2			0x138e
			IMX95_PAD_SD1_DATA3__USDHC1_DATA3			0x138e
			IMX95_PAD_SD1_DATA4__USDHC1_DATA4			0x138e
			IMX95_PAD_SD1_DATA5__USDHC1_DATA5			0x138e
			IMX95_PAD_SD1_DATA6__USDHC1_DATA6			0x138e
			IMX95_PAD_SD1_DATA7__USDHC1_DATA7			0x138e
			IMX95_PAD_SD1_STROBE__USDHC1_STROBE			0x158e
		>;
	};

	pinctrl_usdhc1_200mhz: usdhc1-200mhzgrp {
		fsl,pins = <
			IMX95_PAD_SD1_CLK__USDHC1_CLK				0x15fe
			IMX95_PAD_SD1_CMD__USDHC1_CMD				0x13fe
			IMX95_PAD_SD1_DATA0__USDHC1_DATA0			0x13fe
			IMX95_PAD_SD1_DATA1__USDHC1_DATA1			0x13fe
			IMX95_PAD_SD1_DATA2__USDHC1_DATA2			0x13fe
			IMX95_PAD_SD1_DATA3__USDHC1_DATA3			0x13fe
			IMX95_PAD_SD1_DATA4__USDHC1_DATA4			0x13fe
			IMX95_PAD_SD1_DATA5__USDHC1_DATA5			0x13fe
			IMX95_PAD_SD1_DATA6__USDHC1_DATA6			0x13fe
			IMX95_PAD_SD1_DATA7__USDHC1_DATA7			0x13fe
			IMX95_PAD_SD1_STROBE__USDHC1_STROBE			0x15fe
		>;
	};

	pinctrl_reg_usdhc2_vmmc: regusdhc2vmmcgrp {
		fsl,pins = <
			IMX95_PAD_SD2_RESET_B__GPIO3_IO_BIT7			0x31e
		>;
	};

	pinctrl_usdhc2_gpio: usdhc2gpiogrp {
		fsl,pins = <
			IMX95_PAD_SD2_CD_B__GPIO3_IO_BIT0			0x31e
		>;
	};

	pinctrl_usdhc2: usdhc2grp {
		fsl,pins = <
			IMX95_PAD_SD2_CLK__USDHC2_CLK				0x158e
			IMX95_PAD_SD2_CMD__USDHC2_CMD				0x138e
			IMX95_PAD_SD2_DATA0__USDHC2_DATA0			0x138e
			IMX95_PAD_SD2_DATA1__USDHC2_DATA1			0x138e
			IMX95_PAD_SD2_DATA2__USDHC2_DATA2			0x138e
			IMX95_PAD_SD2_DATA3__USDHC2_DATA3			0x138e
			IMX95_PAD_SD2_VSELECT__USDHC2_VSELECT			0x51e
		>;
	};

	pinctrl_usdhc2_100mhz: usdhc2-100mhzgrp {
		fsl,pins = <
			IMX95_PAD_SD2_CLK__USDHC2_CLK				0x158e
			IMX95_PAD_SD2_CMD__USDHC2_CMD				0x138e
			IMX95_PAD_SD2_DATA0__USDHC2_DATA0			0x138e
			IMX95_PAD_SD2_DATA1__USDHC2_DATA1			0x138e
			IMX95_PAD_SD2_DATA2__USDHC2_DATA2			0x138e
			IMX95_PAD_SD2_DATA3__USDHC2_DATA3			0x138e
			IMX95_PAD_SD2_VSELECT__USDHC2_VSELECT			0x51e
		>;
	};

	pinctrl_usdhc2_200mhz: usdhc2-200mhzgrp {
		fsl,pins = <
			IMX95_PAD_SD2_CLK__USDHC2_CLK				0x15fe
			IMX95_PAD_SD2_CMD__USDHC2_CMD				0x13fe
			IMX95_PAD_SD2_DATA0__USDHC2_DATA0			0x13fe
			IMX95_PAD_SD2_DATA1__USDHC2_DATA1			0x13fe
			IMX95_PAD_SD2_DATA2__USDHC2_DATA2			0x13fe
			IMX95_PAD_SD2_DATA3__USDHC2_DATA3			0x13fe
			IMX95_PAD_SD2_VSELECT__USDHC2_VSELECT			0x51e
		>;
	};

	pinctrl_usdhc3: usdhc3grp {
		fsl,pins = <
			IMX95_PAD_SD3_CLK__USDHC3_CLK				0x158e
			IMX95_PAD_SD3_CMD__USDHC3_CMD				0x138e
			IMX95_PAD_SD3_DATA0__USDHC3_DATA0			0x138e
			IMX95_PAD_SD3_DATA1__USDHC3_DATA1			0x138e
			IMX95_PAD_SD3_DATA2__USDHC3_DATA2			0x138e
			IMX95_PAD_SD3_DATA3__USDHC3_DATA3			0x138e
		>;
	};
	pinctrl_typec: typec1grp {
		fsl,pins = <
			IMX95_PAD_GPIO_IO35__GPIO5_IO_BIT15			0x176
		>;
	};
};

&vpuctrl {
	boot = <&vpu_boot>;
	sram = <&sram1>;
};

&wdog3 {
	status = "okay";
};
/*
&pcie0 {
	pinctrl-0 = <&pinctrl_pcie0>;
	pinctrl-names = "default";
	fsl,refclk-pad-mode = <IMX8_PCIE_REFCLK_PAD_OUTPUT>;
	reset-gpio = <&i2c7_pcal6524 5 GPIO_ACTIVE_LOW>;
	//vpcie-supply = <&reg_pcie0>;
	status = "disabled";
};

&pcie1 {
	pinctrl-0 = <&pinctrl_pcie1>;
	pinctrl-names = "default";
	fsl,refclk-pad-mode = <IMX8_PCIE_REFCLK_PAD_OUTPUT>;
	reset-gpio = <&i2c7_pcal6524 16 GPIO_ACTIVE_LOW>;
	status = "disabled";
};
*/
&sai1 {
	#sound-dai-cells = <0>;
	pinctrl-names = "default";
	pinctrl-0 = <&pinctrl_sai1>;
	assigned-clocks = <&scmi_clk IMX95_CLK_AUDIOPLL1_VCO>,
			  <&scmi_clk IMX95_CLK_AUDIOPLL2_VCO>,
			  <&scmi_clk IMX95_CLK_AUDIOPLL1>,
			  <&scmi_clk IMX95_CLK_AUDIOPLL2>,
			  <&scmi_clk IMX95_CLK_SAI1>;
	assigned-clock-parents = <0>, <0>, <0>, <0>,
				 <&scmi_clk IMX95_CLK_AUDIOPLL1>;
	assigned-clock-rates = <3932160000>,
			       <3612672000>, <393216000>,
			       <361267200>, <12288000>;
	fsl,sai-mclk-direction-output;
	status = "okay";
};

&sai3 {
	#sound-dai-cells = <0>;
	pinctrl-names = "default";
	pinctrl-0 = <&pinctrl_sai3>;
	assigned-clocks = <&scmi_clk IMX95_CLK_AUDIOPLL1_VCO>,
			  <&scmi_clk IMX95_CLK_AUDIOPLL2_VCO>,
			  <&scmi_clk IMX95_CLK_AUDIOPLL1>,
			  <&scmi_clk IMX95_CLK_AUDIOPLL2>,
			  <&scmi_clk IMX95_CLK_SAI3>;
	assigned-clock-parents = <0>, <0>, <0>, <0>,
				 <&scmi_clk IMX95_CLK_AUDIOPLL1>;
	assigned-clock-rates = <3932160000>,
			       <3612672000>, <393216000>,
			       <361267200>, <12288000>;
	fsl,sai-mclk-direction-output;
	status = "okay";
};

&micfil {
	#sound-dai-cells = <0>;
	pinctrl-names = "default";
	pinctrl-0 = <&pinctrl_pdm>;
	assigned-clocks = <&scmi_clk IMX95_CLK_AUDIOPLL1_VCO>,
			  <&scmi_clk IMX95_CLK_AUDIOPLL2_VCO>,
			  <&scmi_clk IMX95_CLK_AUDIOPLL1>,
			  <&scmi_clk IMX95_CLK_AUDIOPLL2>,
			  <&scmi_clk IMX95_CLK_PDM>;
	assigned-clock-parents = <0>, <0>, <0>, <0>,
				 <&scmi_clk IMX95_CLK_AUDIOPLL1>;
	assigned-clock-rates = <3932160000>,
			       <3612672000>, <393216000>,
			       <361267200>, <49152000>;
	status = "disabled";
};

/ {
	lvds0_panel {
		compatible = "forlinx,panel", "panel-lvds";
		panel-type = "lvds";
		status = "okay";

		width-mm = <218>;
		height-mm = <138>;
		data-mapping = "vesa-24";
		bmp-logo = "logo-1280x800.bmp";

		panel-timing {
			hback-porch		= <10>;
			hfront-porch	= <120>;
			hactive			= <1280>;
			hsync-len		= <10>;
			vback-porch		= <1>;
			vfront-porch	= <2>;
			vactive			= <800>;
			vsync-len		= <20>;
			clock-frequency	= <72000000>;
			hsync-active	= <1>;
			vsync-active	= <1>;
			de-active		= <1>;
		};

		ports {
			#address-cells = <1>;
			#size-cells = <0>;

			port@0 {
				reg = <0>;
				panel_in_lvds0: endpoint {
					remote-endpoint = <&lvds0_out>;
				};
			};
		};
	};
};

&display_pixel_link {
	status = "okay";
};

&ldb {
	#address-cells = <1>;
	#size-cells = <0>;
	assigned-clocks = <&scmi_clk IMX95_CLK_LDBPLL_VCO>,
			  <&scmi_clk IMX95_CLK_LDBPLL>;
	assigned-clock-rates = <1645560000>, <548520000>;
	status = "okay";

	channel@0 {
		#address-cells = <1>;
		#size-cells = <0>;
		reg = <0>;
		status = "okay";

		port@1 {
			reg = <1>;

			lvds0_out: endpoint {
				remote-endpoint = <&panel_in_lvds0>;
			};
		};
	};

};

&ldb0_phy {
	status = "okay";
};

&pixel_interleaver {
	#address-cells = <1>;
	#size-cells = <0>;
	status = "okay";

	channel@0 {
		reg = <0>;
		status = "okay";
	};

	channel@1 {
		reg = <1>;
		status = "okay";
	};
};


&mipi_dsi {
	#address-cells = <1>;
	#size-cells = <0>;
	status = "okay";

	panel@0 {
		compatible = "forlinx,panel-mipi7";
		reg = <0>;
		enable-gpio = <&i2c2_pcal6524 17 GPIO_ACTIVE_LOW>;
		dsi-lanes = <4>;
		v3p3-supply = <&reg_3p3v>;
		v1p8-supply = <&reg_1p8v>;
		width-mm = <153>;
		height-mm = <81>;
		backlight = <&mipi_backlight>;

		display-timings { //kernel
			panel7_1024x600_kernel: timings {
				hback-porch     = <70>;
				hfront-porch    = <153>;
				hactive         = <1024>;
				hsync-len       = <153>;
				vback-porch     = <10>;
				vfront-porch    = <45>;
				vactive         = <600>;
				vsync-len       = <45>;
				clock-frequency = <74250000>;
				vsync-active    = <0>;
				hsync-active    = <0>;
				de-active       = <0>;
				pixelclk-active = <0>;
			};
		};

		port {
			panel_in: endpoint {
				remote-endpoint = <&dsi_out>;
			};
		};
	};

	ports {
		#address-cells = <1>;
		#size-cells = <0>;

		port@1 {
			reg = <1>;

			dsi_out: endpoint {
				remote-endpoint = <&panel_in>;
			};
		};
	};
};

&dphy_rx {
	status = "okay";
};

&mipi_csi0 {
	status = "okay";

	ports {
		#address-cells = <1>;
		#size-cells = <0>;

		port@0 {
			reg = <0>;
			mipi_csi0_ep: endpoint {
				remote-endpoint = <&mipi_cam0_ep>;
				data-lanes = <1 2>;
				clock-lanes = <0>;
				link-frequencies = /bits/ 64 <336000000>;
			};
		};

		port@1 {
			reg = <1>;
				mipi_csi0_out: endpoint {
				remote-endpoint = <&isi_in_2>;
			};
		};
	};
};

&isi {
	status = "okay";

	ports {
		#address-cells = <1>;
		#size-cells = <0>;

		port@2 {
			reg = <2>;

			isi_in_2: endpoint {
				remote-endpoint = <&mipi_csi0_out>;
			};
		};
	};
};

// disable rtc in cpu
&scmi_bbm {
	status = "disabled";
};
